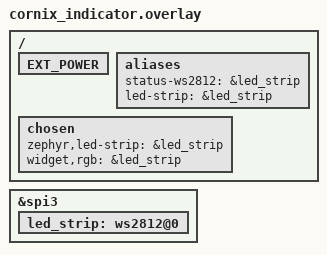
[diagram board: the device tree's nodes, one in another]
&spi3 {
    status = "okay";

    led_strip: ws2812@0 {
        status = "okay";
    };
};

// Behavior nodes (&show_status etc.) come from config/cornix.keymap, which
// includes <behaviors/rgbled_widget.dtsi> unconditionally.

/ {
    EXT_POWER {
        status = "okay";
    };

    aliases {
        status-ws2812 = &led_strip;
        led-strip = &led_strip;
    };

    chosen {
        zephyr,led-strip = &led_strip;
        widget,rgb = &led_strip;
    };
};
